# DMASS_PKTDMA_0_DMASS_PKTDMA_0_PKTDMA_CHAN_48210000h register map
Vendor: Texas Instruments
Peripheral module from a debugger description file (folder am62L).
Registers are 32-bit, read-write, reset 0x0 unless marked. A register's access mark holds for its fields unless they carry their own. Offsets are as the file gives them; lines under a group give offsets from that group; [hi:lo] are bit positions; {n}, {i} and the like mark numbered series; 'fields as' and 'values as' point back to an identical list; <NAME> marks a mode.

## DMASS_PKTDMA_0_PKTDMA_CHAN
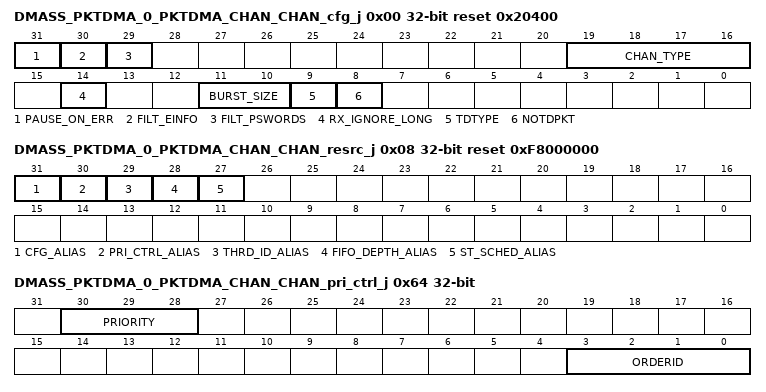
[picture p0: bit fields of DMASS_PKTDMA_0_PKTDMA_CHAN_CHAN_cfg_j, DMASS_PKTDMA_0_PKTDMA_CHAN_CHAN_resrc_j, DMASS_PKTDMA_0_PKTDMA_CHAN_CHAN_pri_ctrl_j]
0x00 DMASS_PKTDMA_0_PKTDMA_CHAN_CHAN_cfg_j reset 0x20400 — The Channel Configuration Register is used to initialize static mode settings for the DMA channel. This register may only be written when the channel is disabled (enable in realtime control reg is 0).
  [31] PAUSE_ON_ERR — Pause On Error: this field controls what the channel will do if an error or exception occurs during a data transfer. This field is encoded as follows: 0 = Channel will report error and continue current work and move on when finished 1 = Channel will pause and wait for SW to investigate and un-pause the channel. Reset Source: rst_mod_g_rst_n
  [30] FILT_EINFO — This field controls whether or not the DMA controller will pass the extended packet information fields (if present) from the descriptor to the back end application. 0 DMA controller will pass extended packet info words if they are present in the descriptor1 DMA controller will filter extended packet info words.
  [29] FILT_PSWORDS — This field controls whether or not the DMA controller will pass the protocol specific words (if present) from the descriptor to the back end application. 0 DMA controller will pass extended PS words if they are present in the descriptor1 DMA controller will filter PS words.
  [19:16] CHAN_TYPE — Channel Type: this field controls and / or indicates the functional channel type for this channel and the work passing mechanism that the channel uses for communicating with the Host. 0 Channel is not a valid channel for this DMA2 Channel performs packet oriented data transfers using pass by reference rings. Channels configured in this mode can only use Host and Monolithic descriptors and the pointers to those descriptors are passed from/to SW using rings3 Channel performs packet oriented data transfers using pass by reference rings with single buffer packet mode enabled. Channels configured in this mode can only use Host descriptors and each descriptor will be processed as an independent packet (no buffer chaining). This is the only packet oriented mode that can be used with data sources that are infinite streams (no EOP) and is only available for RX channels
  [14] RX_IGNORE_LONG — This field controls whether or not long packets will be treated as exceptions or ignored for the channel. This field is only used when the channel is in split UTC mode. The values are encoded as follows: 0 = Long packets are treated as exceptions and handled appropriately. 1 = Long packets are ignored and the next TR will be fetched even if the current TR is marked or interpreted as EOP. This bit is only valid for RX channel. Reset Source: rst_mod_g_rst_n
  [11:10] BURST_SIZE — Specifies the nominal burst size and alignment for data transfers on this channel. The optimal burst size setting is to maximize utilization of the channel FIFOs. Reset Source: rst_mod_g_rst_n
  [9] TDTYPE — Specifies whether or not the channel should immediately return a teardown completion response to the default completion queue or wait until a status message is returned from the remote PSI-L paired peripheral. 0 = return immediately once all traffic is complete in PKTDMA. 1 = wait until remote peer sends back a completion message. This field is only valid if the channel is for a TX peripheral otherwise it is reserved. It is assumed that if the TX peripheral sends a tdown completion message it also sends EOP completion messages. Setting this bit enables delaying of TX completion events until the EOP completion message is received as well. Reset Source: rst_mod_g_rst_n
  [8] NOTDPKT — Specifies whether or not the channel should suppress sending the single data phase teardown packet when teardown is complete. 0 = TD packet is sent 1 = Suppress sending TD packet. This field is only valid for a TX peripherial otherwise it is reserved Reset Source: rst_mod_g_rst_n
0x08 DMASS_PKTDMA_0_PKTDMA_CHAN_CHAN_resrc_j reset 0xF8000000 — The Resource Register determines if certain resources remain only in the configuration register or can be aliased in the real-time region to allow for a user process to manage the channel itself.
  [31] CFG_ALIAS — Allow the Channel Configuration Registers to appear in the Real-Time region to allow for the channel to be torn down or burst adjusted by the user process. Reset Source: rst_mod_g_rst_n
  [30] PRI_CTRL_ALIAS — Allow the priority control register to be accessed in the Real-time region Reset Source: rst_mod_g_rst_n
  [29] THRD_ID_ALIAS — Allow the thread ID register to be accessed in the Real-time region Reset Source: rst_mod_g_rst_n
  [28] FIFO_DEPTH_ALIAS — Allow the FIFO Depth register to be accessed in the Real-time region Reset Source: rst_mod_g_rst_n
  [27] ST_SCHED_ALIAS — Allow the Static Scheduler register to be accessed in the Real-time region Reset Source: rst_mod_g_rst_n
0x64 DMASS_PKTDMA_0_PKTDMA_CHAN_CHAN_pri_ctrl_j — The priority control register is used to control the priority of the transactions which the DMA generates on it's master interface.
  [30:28] PRIORITY — Priority: This field contains the 3-bit value which will be output on the mem*_cpriority and mem_cepriority outputs during all transactions for this channel. Reset Source: rst_mod_g_rst_n
  [3:0] ORDERID — Order ID: This field contains the 4-bit value which will be output on the mem*_corderid output during all transactions for this channel. Reset Source: rst_mod_g_rst_n
0x68 DMASS_PKTDMA_0_PKTDMA_CHAN_CHAN_thread_j — The thread ID mapping register is used to pair the DMA channel to a specific destination thread. All traffic generated from this channel will be sent with a thread_id on the PSI-L interface with the value from this register. This register is only valid if the channel is a TX or RX peripheral channel.
  [15:0] THREAD_ID — This field contains the (up-to) 16-bit value which will be output on the strm_o_thread_id output during all transactions for this channel. The reset value is set based on the configuration for the DMA and value is determined by the channel table. Reset Source: rst_mod_g_rst_n
0x70 DMASS_PKTDMA_0_PKTDMA_CHAN_CHAN_fifo_depth_j reset 0xC0 — The fifo depth register is used to specify how many FIFO data phases deep the Tx per channel FIFO will be for the channel. While the maximum depth of the Tx FIFO is set at design time, the FIFO depth can be artificially reduced in order to control the maximum latency which can be introduced due to buffering effects. This register only exists if this channel is a TX peripheral channel otherwise it is reserved.
  [7:0] FDEPTH — This field contains the number of Tx FIFO bytes which will be allowed to be stored for the channel. The minimum value is equal to the PSI-L interface data path width (tstrm_wdth), the maximum value varies by channel class (ultra-high capacity/high capacity/normal capacity) and is equal to the tubuf_size/thbuf_size/tbuf_size parameter respectively multiplied by the PSI-L data path width (tstrm_wdth). The fdepth must always be an integer multiple of 16. The reset value of this register varies by channel but will be equal to the value for the specific channel. Do NOT modify if the channel is going to be used in loopback and send mode for XLCDMA. Reset Source: rst_mod_g_rst_n
0x80 DMASS_PKTDMA_0_PKTDMA_CHAN_CHAN_tst_sched_j — The Channel N Static Scheduler Configuration Register contains static configuration information which affects the conditions under which each channel will be given an opportunity to use the Tx DMA unit(s). The fields in this register are as follows:
  [1:0] PRIORITY — These bits select which scheduling bin the channel will be placed in for bandwidth allocation of the Tx/Rx DMA units. This field is encoded as follows: 0 = High priority 1 = Medium - high priority 2 = Medium - low priority 3 = Low priority Arbitration between bins is performed in a strict priority fashion. High priority channels will always be serviced first. If no high priority channels are requesting then all medium-high priority channels will be serviced next. If no high priority or medium-high priority channels are requesting then all medium-low priority channels will be serviced next. When no other channels are requesting, the low priority channels will be serviced. All channels within a given bin are serviced in a round robin order. Only channels which are enabled and which have sufficient free space in their Per Channel FIFO will be included in the round robin arbitration. Reset Source: rst_mod_g_rst_n
